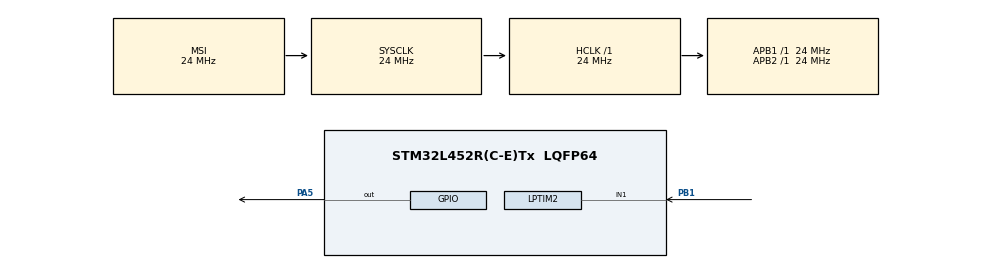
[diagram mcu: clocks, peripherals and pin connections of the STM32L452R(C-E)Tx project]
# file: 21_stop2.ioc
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Mcu.Family=STM32L4
Mcu.Name=STM32L452R(C-E)Tx
Mcu.Package=LQFP64
NVIC.PriorityGroup=NVIC_PRIORITYGROUP_4
PA13\ (JTMS/SWDIO).GPIO_Label=TMS
PA13\ (JTMS/SWDIO).Mode=Serial_Wire
PA13\ (JTMS/SWDIO).Signal=SYS_JTMS-SWDIO
PA14\ (JTCK/SWCLK).GPIO_Label=TCK
PA14\ (JTCK/SWCLK).Mode=Serial_Wire
PA14\ (JTCK/SWCLK).Signal=SYS_JTCK-SWCLK
PA5.Signal=GPIO_Output
PB1.Mode=Counts_external_clock_standalone_1X_occur1
PB1.Signal=LPTIM2_IN1
PC14-OSC32_IN\ (PC14).Mode=LSE-External-Oscillator
PC14-OSC32_IN\ (PC14).Signal=RCC_OSC32_IN
PC15-OSC32_OUT\ (PC15).Mode=LSE-External-Oscillator
PC15-OSC32_OUT\ (PC15).Signal=RCC_OSC32_OUT
ProjectManager.HeapSize=0x200
ProjectManager.StackSize=0x400
ProjectManager.TargetToolchain=STM32CubeIDE
RCC.ADCFreq_Value=96000000
RCC.AHBFreq_Value=24000000
RCC.APB1Freq_Value=24000000
RCC.APB1TimFreq_Value=24000000
RCC.APB2Freq_Value=24000000
RCC.APB2TimFreq_Value=24000000
RCC.CortexFreq_Value=24000000
RCC.HCLKFreq_Value=24000000
RCC.HSE_VALUE=8000000
RCC.HSI48_VALUE=48000000
RCC.HSI_VALUE=16000000
RCC.LPTIM1CLockSelection=RCC_LPTIM1CLKSOURCE_LSE
RCC.LPTIM2CLockSelection=RCC_LPTIM2CLKSOURCE_LSE
RCC.MSIClockRange=RCC_MSIRANGE_9
RCC.MSI_VALUE=24000000
RCC.PLLN=16
RCC.PREFETCH_ENABLE=1
RCC.SYSCLKFreq_VALUE=24000000
RCC.USBFreq_Value=96000000
RCC.VCOOutputFreq_Value=384000000
VP_LPTIM1_VS_LPTIM_counterModeInternalClock.Mode=Counts__internal_clock_event_00
board=NUCLEO-L452RE

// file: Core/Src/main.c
/* USER CODE BEGIN Header */
/**
  ******************************************************************************
  * @file           : main.c
  * @brief          : Main program body
  ******************************************************************************
  * @attention
  *
  * Copyright (c) 2022 STMicroelectronics.
  * All rights reserved.
  *
  * This software is licensed under terms that can be found in the LICENSE file
  * in the root directory of this software component.
  * If no LICENSE file comes with this software, it is provided AS-IS.
  *
  ******************************************************************************
  */
/* USER CODE END Header */
#include "main.h"

/* USER CODE BEGIN Includes */
#include "string.h"

/* USER CODE END Includes */

LPTIM_HandleTypeDef hlptim1;
LPTIM_HandleTypeDef hlptim2;

void SystemClock_Config(void);
static void MX_GPIO_Init(void);
static void MX_LPTIM1_Init(void);
static void MX_LPTIM2_Init(void);

int main(void)
{

  /* MCU Configuration--------------------------------------------------------*/

  /* Reset of all peripherals, Initializes the Flash interface and the Systick. */
  HAL_Init();

  /* Configure the system clock */
  SystemClock_Config();

  /* Initialize all configured peripherals */
  MX_GPIO_Init();
  MX_LPTIM1_Init();
  MX_LPTIM2_Init();

  /* Infinite loop */
  /* USER CODE BEGIN WHILE */
  //char buf[80] = "Inicio OK\n\r";
  //unsigned buf_len;

  while (1)
  {
    //buf_len = strlen(buf);
    //HAL_UART_Transmit(&huart2, (const uint8_t *)buf, buf_len, 100);

    HAL_Delay(1);
    HAL_GPIO_WritePin(GPIOA, GPIO_PIN_5, GPIO_PIN_RESET);
    HAL_Delay(999);
    HAL_GPIO_WritePin(GPIOA, GPIO_PIN_5, GPIO_PIN_SET);

    /* USER CODE END WHILE */

  }
}

void SystemClock_Config(void)
{
  RCC_OscInitTypeDef RCC_OscInitStruct = {0};
  RCC_ClkInitTypeDef RCC_ClkInitStruct = {0};

  /** Configure the main internal regulator output voltage
  */
  if (HAL_PWREx_ControlVoltageScaling(PWR_REGULATOR_VOLTAGE_SCALE1) != HAL_OK)
  {
    Error_Handler();
  }

  /** Configure LSE Drive Capability
  */
  HAL_PWR_EnableBkUpAccess();
  __HAL_RCC_LSEDRIVE_CONFIG(RCC_LSEDRIVE_LOW);

  /** Initializes the RCC Oscillators according to the specified parameters
  * in the RCC_OscInitTypeDef structure.
  */
  RCC_OscInitStruct.OscillatorType = RCC_OSCILLATORTYPE_LSE|RCC_OSCILLATORTYPE_MSI;
  RCC_OscInitStruct.LSEState = RCC_LSE_ON;
  RCC_OscInitStruct.MSIState = RCC_MSI_ON;
  RCC_OscInitStruct.MSICalibrationValue = 0;
  RCC_OscInitStruct.MSIClockRange = RCC_MSIRANGE_9;
  RCC_OscInitStruct.PLL.PLLState = RCC_PLL_NONE;
  if (HAL_RCC_OscConfig(&RCC_OscInitStruct) != HAL_OK)
  {
    Error_Handler();
  }

  /** Initializes the CPU, AHB and APB buses clocks
  */
  RCC_ClkInitStruct.ClockType = RCC_CLOCKTYPE_HCLK|RCC_CLOCKTYPE_SYSCLK
                              |RCC_CLOCKTYPE_PCLK1|RCC_CLOCKTYPE_PCLK2;
  RCC_ClkInitStruct.SYSCLKSource = RCC_SYSCLKSOURCE_MSI;
  RCC_ClkInitStruct.AHBCLKDivider = RCC_SYSCLK_DIV1;
  RCC_ClkInitStruct.APB1CLKDivider = RCC_HCLK_DIV1;
  RCC_ClkInitStruct.APB2CLKDivider = RCC_HCLK_DIV1;

  if (HAL_RCC_ClockConfig(&RCC_ClkInitStruct, FLASH_LATENCY_1) != HAL_OK)
  {
    Error_Handler();
  }

  /** Enable MSI Auto calibration
  */
  HAL_RCCEx_EnableMSIPLLMode();
}

static void MX_LPTIM1_Init(void)
{

  hlptim1.Instance = LPTIM1;
  hlptim1.Init.Clock.Source = LPTIM_CLOCKSOURCE_APBCLOCK_LPOSC;
  hlptim1.Init.Clock.Prescaler = LPTIM_PRESCALER_DIV1;
  hlptim1.Init.Trigger.Source = LPTIM_TRIGSOURCE_SOFTWARE;
  hlptim1.Init.OutputPolarity = LPTIM_OUTPUTPOLARITY_HIGH;
  hlptim1.Init.UpdateMode = LPTIM_UPDATE_IMMEDIATE;
  hlptim1.Init.CounterSource = LPTIM_COUNTERSOURCE_INTERNAL;
  hlptim1.Init.Input1Source = LPTIM_INPUT1SOURCE_GPIO;
  hlptim1.Init.Input2Source = LPTIM_INPUT2SOURCE_GPIO;
  if (HAL_LPTIM_Init(&hlptim1) != HAL_OK)
  {
    Error_Handler();
  }

}

static void MX_LPTIM2_Init(void)
{

  hlptim2.Instance = LPTIM2;
  hlptim2.Init.Clock.Source = LPTIM_CLOCKSOURCE_ULPTIM;
  hlptim2.Init.Clock.Prescaler = LPTIM_PRESCALER_DIV1;
  hlptim2.Init.UltraLowPowerClock.Polarity = LPTIM_CLOCKPOLARITY_RISING;
  hlptim2.Init.UltraLowPowerClock.SampleTime = LPTIM_CLOCKSAMPLETIME_DIRECTTRANSITION;
  hlptim2.Init.Trigger.Source = LPTIM_TRIGSOURCE_SOFTWARE;
  hlptim2.Init.OutputPolarity = LPTIM_OUTPUTPOLARITY_HIGH;
  hlptim2.Init.UpdateMode = LPTIM_UPDATE_IMMEDIATE;
  hlptim2.Init.CounterSource = LPTIM_COUNTERSOURCE_EXTERNAL;
  hlptim2.Init.Input1Source = LPTIM_INPUT1SOURCE_GPIO;
  hlptim2.Init.Input2Source = LPTIM_INPUT2SOURCE_GPIO;
  if (HAL_LPTIM_Init(&hlptim2) != HAL_OK)
  {
    Error_Handler();
  }

}

static void MX_GPIO_Init(void)
{
  GPIO_InitTypeDef GPIO_InitStruct = {0};

  /* GPIO Ports Clock Enable */
  __HAL_RCC_GPIOC_CLK_ENABLE();
  __HAL_RCC_GPIOA_CLK_ENABLE();
  __HAL_RCC_GPIOB_CLK_ENABLE();

  /*Configure GPIO pin Output Level */
  HAL_GPIO_WritePin(GPIOA, GPIO_PIN_5, GPIO_PIN_RESET);

  /*Configure GPIO pin : PA5 */
  GPIO_InitStruct.Pin = GPIO_PIN_5;
  GPIO_InitStruct.Mode = GPIO_MODE_OUTPUT_PP;
  GPIO_InitStruct.Pull = GPIO_NOPULL;
  GPIO_InitStruct.Speed = GPIO_SPEED_FREQ_LOW;
  HAL_GPIO_Init(GPIOA, &GPIO_InitStruct);

}

void Error_Handler(void)
{
  __disable_irq();
  while (1)
  {
  }
}
